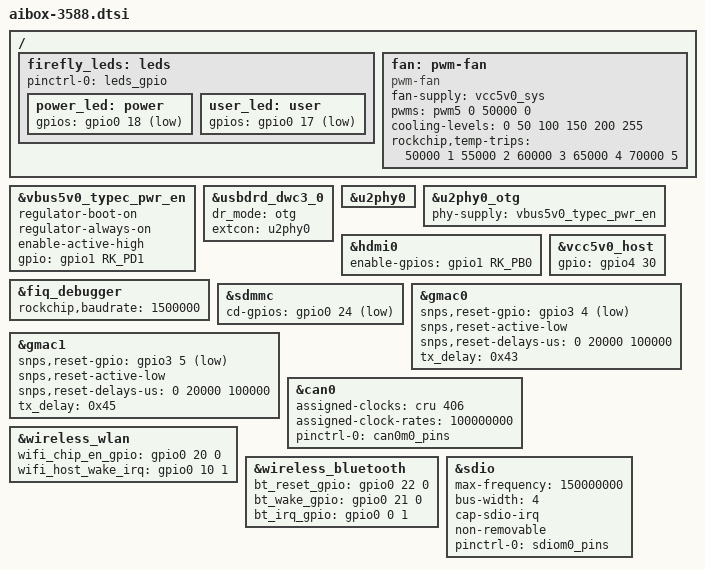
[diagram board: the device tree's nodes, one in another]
// SPDX-License-Identifier: (GPL-2.0+ OR MIT)
/*
 */
 
#define rk3588
#include "rk3588-firefly-port.dtsi"
#include "rk3588-diff.dtsi"

#define M2_SATA_OR_PCIE 0 /*1 = SATA , 0 = PCIe */
#define TYPEC_OTG_20 0    /*1 = OTG , 0 = HOST */

/ {
    firefly_leds: leds {
        pinctrl-names = "default";
        pinctrl-0 = <&leds_gpio>;
        power_led: power {
            gpios = <&gpio0 18 1>; 
        };
        user_led: user {
            gpios = <&gpio0 17 1>;
        };
    };

    fan: pwm-fan {
        compatible = "pwm-fan";
        #cooling-cells = <2>;
        fan-supply = <&vcc5v0_sys>;
        pwms = <&pwm5 0 50000 0>;
        cooling-levels = <0 50 100 150 200 255>;
        rockchip,temp-trips = <
            50000   1
            55000   2
            60000   3
            65000   4
            70000   5
        >;
    };
};

#if TYPEC_OTG_20
&vbus5v0_typec_pwr_en {
    status = "okay";
    gpio = <&gpio1 RK_PD1 GPIO_ACTIVE_HIGH>; 
};
#else
&vbus5v0_typec_pwr_en {
    status = "okay";
    regulator-boot-on;
    regulator-always-on;
    enable-active-high;
    gpio = <&gpio1 RK_PD1 GPIO_ACTIVE_HIGH>;
};
#endif

&usbdrd_dwc3_0 {
    status = "okay";
    dr_mode = "otg"; 
    extcon = <&u2phy0>; 
};

&u2phy0 {
    status = "okay";
};

&u2phy0_otg {
    status = "okay";
    phy-supply = <&vcc5v0_host>; 
};

/delete-node/ &usbc0;
/delete-node/ &usbc0_int;

&u2phy0 {
    status = "okay";
};

&u2phy0_otg { 
   phy-supply  = <&vbus5v0_typec_pwr_en>;
   status = "okay";
}; 


&hdmi0 {
    enable-gpios = <&gpio1 RK_PB0 GPIO_ACTIVE_HIGH>;
    status = "okay";
};

&fiq_debugger {
    rockchip,baudrate = <1500000>; /* 修正为标准 1.5M 波特率 */
};

&vcc5v0_host {
    gpio = <&gpio4 30 0>; 
    status = "okay";
};

&sdmmc {
    cd-gpios = <&gpio0 24 1>; 
    status = "okay";
};

&gmac0 {
    snps,reset-gpio = <&gpio3 4 1>; /* GPIO3_A4 */
    snps,reset-active-low;
    snps,reset-delays-us = <0 20000 100000>;
    tx_delay = <0x43>; 
    status = "okay";
};

&gmac1 {
    snps,reset-gpio = <&gpio3 5 1>; /* GPIO3_A5 */
    snps,reset-active-low;
    snps,reset-delays-us = <0 20000 100000>;
    tx_delay = <0x45>;
    status = "okay";
};

&can0 {
    status = "okay";
    assigned-clocks = <&cru 406>; 
    assigned-clock-rates = <100000000>; 
    pinctrl-names = "default";
    pinctrl-0 = <&can0m0_pins>; 
};

&wireless_wlan {
    wifi_chip_en_gpio = <&gpio0 20 0>; /* GPIO0_C4 */
    wifi_host_wake_irq = <&gpio0 10 1>; /* GPIO0_B2 */
    status = "okay";
};

&wireless_bluetooth {
    bt_reset_gpio = <&gpio0 22 0>; /* GPIO0_C6 */
    bt_wake_gpio = <&gpio0 21 0>;  /* GPIO0_C5 */
    bt_irq_gpio = <&gpio0 0 1>;    /* GPIO0_A0 */
    status = "okay";
};

&sdio {
    max-frequency = <150000000>;
    bus-width = <4>;
    cap-sdio-irq;
    non-removable;
    pinctrl-names = "default";
    pinctrl-0 = <&sdiom0_pins>;  
    status = "okay";
};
